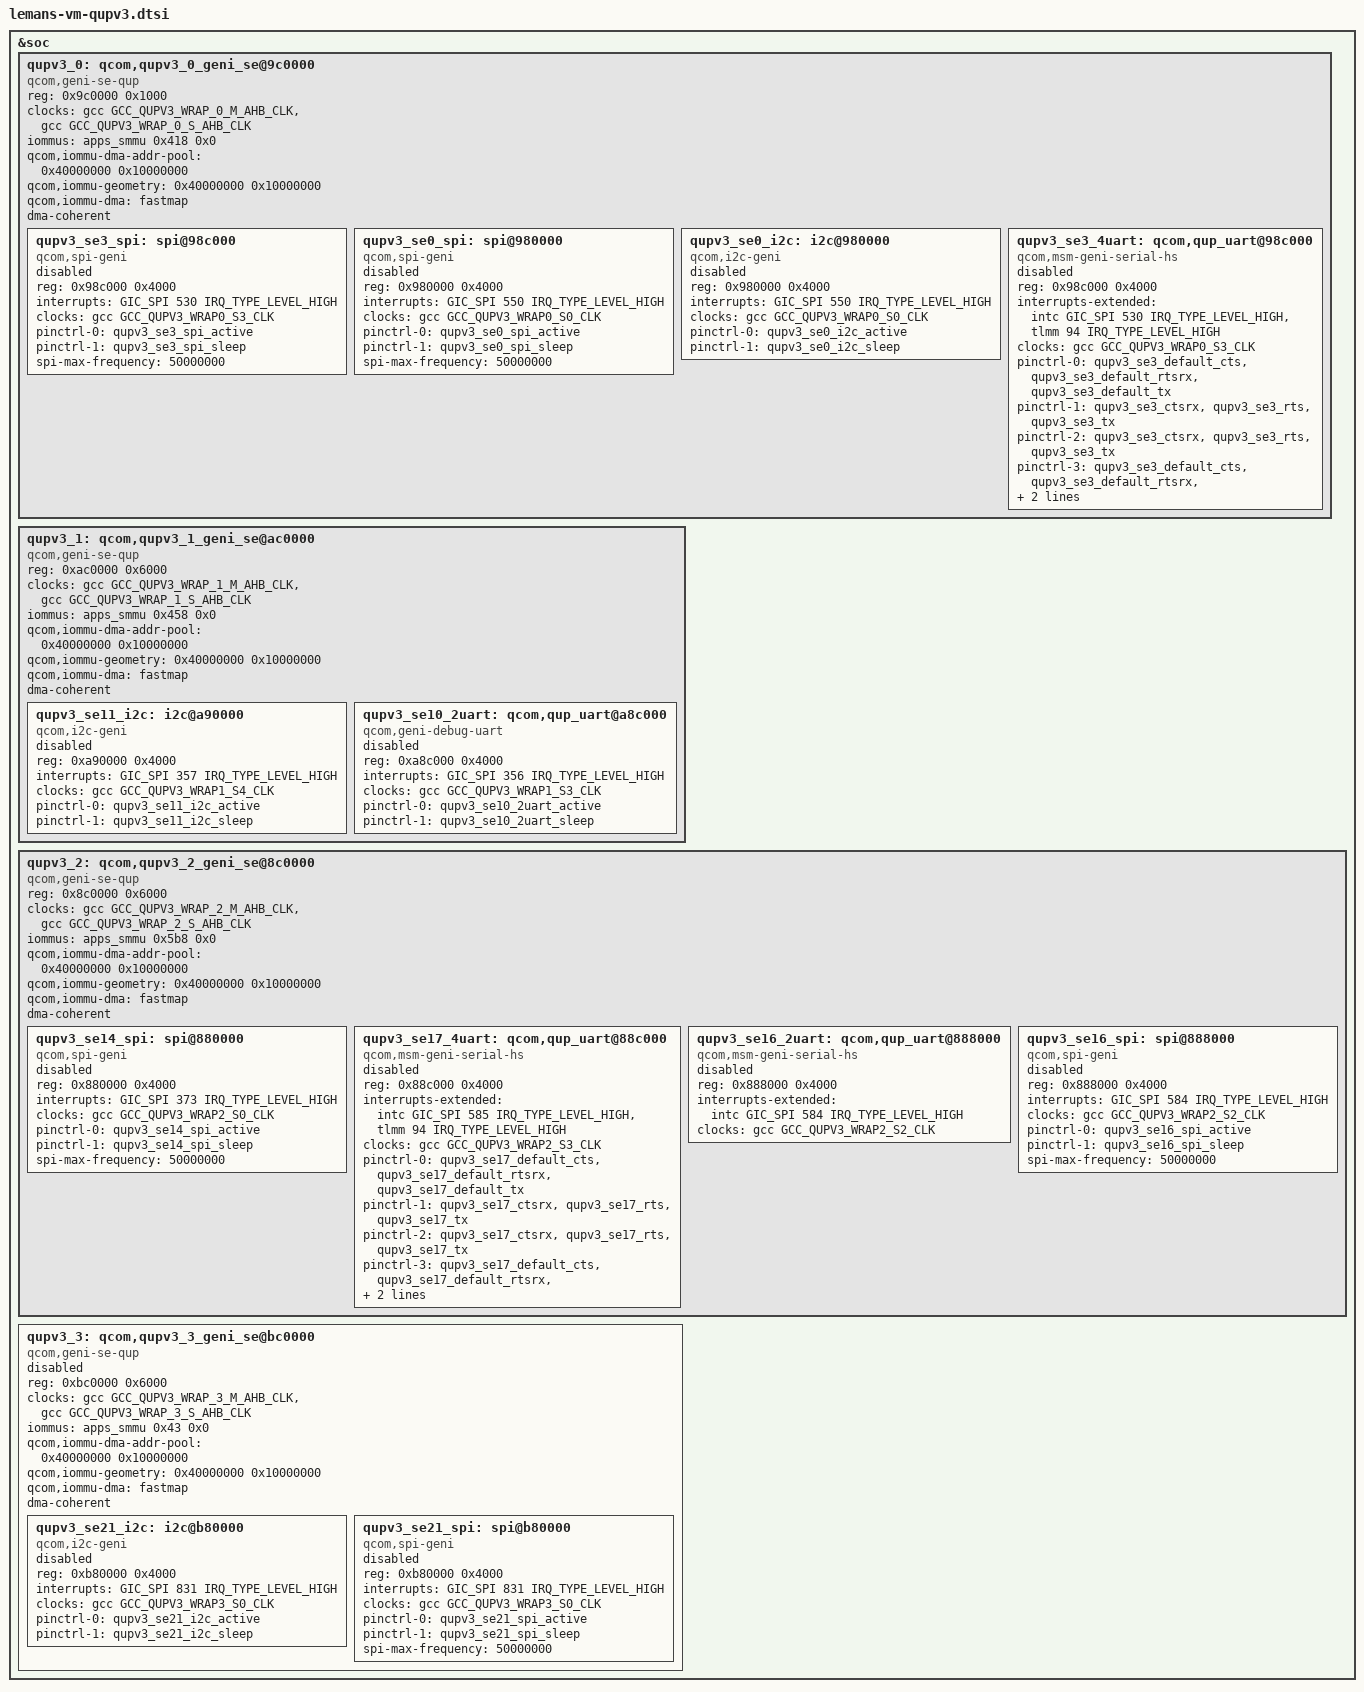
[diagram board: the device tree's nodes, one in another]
&soc {
	/* QUPv3_0  wrapper  instance */
	qupv3_0: qcom,qupv3_0_geni_se@9c0000 {
		compatible = "qcom,geni-se-qup";
		reg = <0x9c0000 0x1000>;
		#address-cells = <1>;
		#size-cells = <1>;
		ranges;
		clock-names = "m-ahb", "s-ahb";
		clocks = <&gcc GCC_QUPV3_WRAP_0_M_AHB_CLK>,
			<&gcc GCC_QUPV3_WRAP_0_S_AHB_CLK>;
		iommus = <&apps_smmu 0x418 0x0>;
		qcom,iommu-dma-addr-pool = <0x40000000 0x10000000>;
		qcom,iommu-geometry = <0x40000000 0x10000000>;
		qcom,iommu-dma = "fastmap";
		dma-coherent;
		status = "ok";

		qupv3_se3_spi: spi@98c000 {
			compatible = "qcom,spi-geni";
			reg = <0x98c000 0x4000>;
			#address-cells = <1>;
			#size-cells = <0>;
			reg-names = "se_phys";
			interrupts = <GIC_SPI 530 IRQ_TYPE_LEVEL_HIGH>;
			clock-names = "se-clk";
			clocks = <&gcc GCC_QUPV3_WRAP0_S3_CLK>;
			pinctrl-names = "default", "sleep";
			pinctrl-0 = <&qupv3_se3_spi_active>;
			pinctrl-1 = <&qupv3_se3_spi_sleep>;
			spi-max-frequency = <50000000>;
			status = "disabled";
		};

		qupv3_se0_spi: spi@980000 {
			compatible = "qcom,spi-geni";
			reg = <0x980000 0x4000>;
			#address-cells = <1>;
			#size-cells = <0>;
			reg-names = "se_phys";
			interrupts = <GIC_SPI 550 IRQ_TYPE_LEVEL_HIGH>;
			clock-names = "se-clk";
			clocks = <&gcc GCC_QUPV3_WRAP0_S0_CLK>;
			pinctrl-names = "default", "sleep";
			pinctrl-0 = <&qupv3_se0_spi_active>;
			pinctrl-1 = <&qupv3_se0_spi_sleep>;
			spi-max-frequency = <50000000>;
			status = "disabled";
		};

		qupv3_se0_i2c: i2c@980000 {
			compatible = "qcom,i2c-geni";
			reg = <0x980000 0x4000>;
			#address-cells = <1>;
			#size-cells = <0>;
			interrupts = <GIC_SPI 550 IRQ_TYPE_LEVEL_HIGH>;
			clock-names = "se-clk";
			clocks = <&gcc GCC_QUPV3_WRAP0_S0_CLK>;
			pinctrl-names = "default", "sleep";
			pinctrl-0 = <&qupv3_se0_i2c_active>;
			pinctrl-1 = <&qupv3_se0_i2c_sleep>;
			status = "disabled";
		};

		/* BT UART 2nd Hastings Instance */
		qupv3_se3_4uart: qcom,qup_uart@98c000 {
			compatible = "qcom,msm-geni-serial-hs";
			reg = <0x98c000 0x4000>;
			reg-names = "se_phys";
			interrupts-extended = <&intc GIC_SPI 530 IRQ_TYPE_LEVEL_HIGH>,
					<&tlmm 94 IRQ_TYPE_LEVEL_HIGH>;
			clock-names = "se-clk";
			clocks = <&gcc GCC_QUPV3_WRAP0_S3_CLK>;
			pinctrl-names = "default", "active", "sleep", "shutdown";
			pinctrl-0 = <&qupv3_se3_default_cts>,
					<&qupv3_se3_default_rtsrx>, <&qupv3_se3_default_tx>;
			pinctrl-1 = <&qupv3_se3_ctsrx>, <&qupv3_se3_rts>,
					<&qupv3_se3_tx>;
			pinctrl-2 = <&qupv3_se3_ctsrx>, <&qupv3_se3_rts>,
					<&qupv3_se3_tx>;
			pinctrl-3 = <&qupv3_se3_default_cts>,
					<&qupv3_se3_default_rtsrx>, <&qupv3_se3_default_tx>;
			qcom,wakeup-byte = <0xFD>;
			status = "disabled";
		};
	};

	/* QUPv3_1  wrapper  instance */
	qupv3_1: qcom,qupv3_1_geni_se@ac0000 {
		compatible = "qcom,geni-se-qup";
		reg = <0xac0000 0x6000>;
		#address-cells = <1>;
		#size-cells = <1>;
		ranges;
		clock-names = "m-ahb", "s-ahb";
		clocks = <&gcc GCC_QUPV3_WRAP_1_M_AHB_CLK>,
			<&gcc GCC_QUPV3_WRAP_1_S_AHB_CLK>;
		iommus = <&apps_smmu 0x458 0x0>;
		qcom,iommu-dma-addr-pool = <0x40000000 0x10000000>;
		qcom,iommu-geometry = <0x40000000 0x10000000>;
		qcom,iommu-dma = "fastmap";
		dma-coherent;
		status = "ok";

		qupv3_se11_i2c: i2c@a90000 {
			compatible = "qcom,i2c-geni";
			reg = <0xa90000 0x4000>;
			#address-cells = <1>;
			#size-cells = <0>;
			interrupts = <GIC_SPI 357 IRQ_TYPE_LEVEL_HIGH>;
			clock-names = "se-clk";
			clocks = <&gcc GCC_QUPV3_WRAP1_S4_CLK>;
			pinctrl-names = "default", "sleep";
			pinctrl-0 = <&qupv3_se11_i2c_active>;
			pinctrl-1 = <&qupv3_se11_i2c_sleep>;
			status = "disabled";
		};

		/* Debug UART Instance */
		qupv3_se10_2uart: qcom,qup_uart@a8c000 {
			compatible = "qcom,geni-debug-uart";
			reg = <0xa8c000 0x4000>;
			reg-names = "se_phys";
			interrupts = <GIC_SPI 356 IRQ_TYPE_LEVEL_HIGH>;
			clock-names = "se";
			clocks = <&gcc GCC_QUPV3_WRAP1_S3_CLK>;
			pinctrl-names = "default", "sleep";
			pinctrl-0 = <&qupv3_se10_2uart_active>;
			pinctrl-1 = <&qupv3_se10_2uart_sleep>;
			status = "disabled";
		};
	};

	/* QUPv3_2  wrapper  instance */
	qupv3_2: qcom,qupv3_2_geni_se@8c0000 {
		compatible = "qcom,geni-se-qup";
		reg = <0x8c0000 0x6000>;
		#address-cells = <1>;
		#size-cells = <1>;
		ranges;
		clock-names = "m-ahb", "s-ahb";
		clocks = <&gcc GCC_QUPV3_WRAP_2_M_AHB_CLK>,
			<&gcc GCC_QUPV3_WRAP_2_S_AHB_CLK>;
		iommus = <&apps_smmu 0x5b8  0x0>;
		qcom,iommu-dma-addr-pool = <0x40000000 0x10000000>;
		qcom,iommu-geometry = <0x40000000 0x10000000>;
		qcom,iommu-dma = "fastmap";
		dma-coherent;
		status = "ok";

		qupv3_se14_spi: spi@880000 {
			compatible = "qcom,spi-geni";
			reg = <0x880000 0x4000>;
			#address-cells = <1>;
			#size-cells = <0>;
			reg-names = "se_phys";
			interrupts = <GIC_SPI 373 IRQ_TYPE_LEVEL_HIGH>;
			clock-names = "se-clk";
			clocks = <&gcc GCC_QUPV3_WRAP2_S0_CLK>;
			pinctrl-names = "default", "sleep";
			pinctrl-0 = <&qupv3_se14_spi_active>;
			pinctrl-1 = <&qupv3_se14_spi_sleep>;
			spi-max-frequency = <50000000>;
			status = "disabled";
		};

		/* BT UART Instance */
		qupv3_se17_4uart: qcom,qup_uart@88c000 {
			compatible = "qcom,msm-geni-serial-hs";
			reg = <0x88c000 0x4000>;
			reg-names = "se_phys";
			interrupts-extended = <&intc GIC_SPI 585 IRQ_TYPE_LEVEL_HIGH>,
					<&tlmm 94 IRQ_TYPE_LEVEL_HIGH>;
			clock-names = "se-clk";
			clocks = <&gcc GCC_QUPV3_WRAP2_S3_CLK>;
			pinctrl-names = "default", "active", "sleep", "shutdown";
			pinctrl-0 = <&qupv3_se17_default_cts>,
					<&qupv3_se17_default_rtsrx>, <&qupv3_se17_default_tx>;
			pinctrl-1 = <&qupv3_se17_ctsrx>, <&qupv3_se17_rts>,
					<&qupv3_se17_tx>;
			pinctrl-2 = <&qupv3_se17_ctsrx>, <&qupv3_se17_rts>,
					<&qupv3_se17_tx>;
			pinctrl-3 = <&qupv3_se17_default_cts>,
					<&qupv3_se17_default_rtsrx>, <&qupv3_se17_default_tx>;
			qcom,wakeup-byte = <0xFD>;
			status = "disabled";
		};

		/* GNSS UART Instance */
		qupv3_se16_2uart: qcom,qup_uart@888000 {
			compatible = "qcom,msm-geni-serial-hs";
			reg = <0x888000 0x4000>;
			reg-names = "se_phys";
			interrupts-extended = <&intc GIC_SPI 584 IRQ_TYPE_LEVEL_HIGH>;
			clock-names = "se-clk";
			clocks = <&gcc GCC_QUPV3_WRAP2_S2_CLK>;
			status = "disabled";
		};

		qupv3_se16_spi: spi@888000 {
			compatible = "qcom,spi-geni";
			reg = <0x888000 0x4000>;
			#address-cells = <1>;
			#size-cells = <0>;
			reg-names = "se_phys";
			interrupts = <GIC_SPI 584 IRQ_TYPE_LEVEL_HIGH>;
			clock-names = "se-clk";
			clocks = <&gcc GCC_QUPV3_WRAP2_S2_CLK>;
			pinctrl-names = "default", "sleep";
			pinctrl-0 = <&qupv3_se16_spi_active>;
			pinctrl-1 = <&qupv3_se16_spi_sleep>;
			spi-max-frequency = <50000000>;
			status = "disabled";
		};
	};

	/* QUPv3_3  wrapper  instance */
	qupv3_3: qcom,qupv3_3_geni_se@bc0000 {
		compatible = "qcom,geni-se-qup";
		reg = <0xbc0000 0x6000>;
		#address-cells = <1>;
		#size-cells = <1>;
		ranges;
		clock-names = "m-ahb", "s-ahb";
		clocks = <&gcc GCC_QUPV3_WRAP_3_M_AHB_CLK>,
			<&gcc GCC_QUPV3_WRAP_3_S_AHB_CLK>;
		iommus = <&apps_smmu 0x43 0x0>;
		qcom,iommu-dma-addr-pool = <0x40000000 0x10000000>;
		qcom,iommu-geometry = <0x40000000 0x10000000>;
		qcom,iommu-dma = "fastmap";
		dma-coherent;
		status = "disabled";

		qupv3_se21_i2c: i2c@b80000 {
			compatible = "qcom,i2c-geni";
			reg = <0xb80000 0x4000>;
			#address-cells = <1>;
			#size-cells = <0>;
			interrupts = <GIC_SPI 831 IRQ_TYPE_LEVEL_HIGH>;
			clock-names = "se-clk";
			clocks = <&gcc GCC_QUPV3_WRAP3_S0_CLK>;
			pinctrl-names = "default", "sleep";
			pinctrl-0 = <&qupv3_se21_i2c_active>;
			pinctrl-1 = <&qupv3_se21_i2c_sleep>;
			status = "disabled";
		};

		qupv3_se21_spi: spi@b80000 {
			compatible = "qcom,spi-geni";
			reg = <0xb80000 0x4000>;
			#address-cells = <1>;
			#size-cells = <0>;
			reg-names = "se_phys";
			interrupts = <GIC_SPI 831 IRQ_TYPE_LEVEL_HIGH>;
			clock-names = "se-clk";
			clocks = <&gcc GCC_QUPV3_WRAP3_S0_CLK>;
			pinctrl-names = "default", "sleep";
			pinctrl-0 = <&qupv3_se21_spi_active>;
			pinctrl-1 = <&qupv3_se21_spi_sleep>;
			spi-max-frequency = <50000000>;
			status = "disabled";
		};
	};
};
